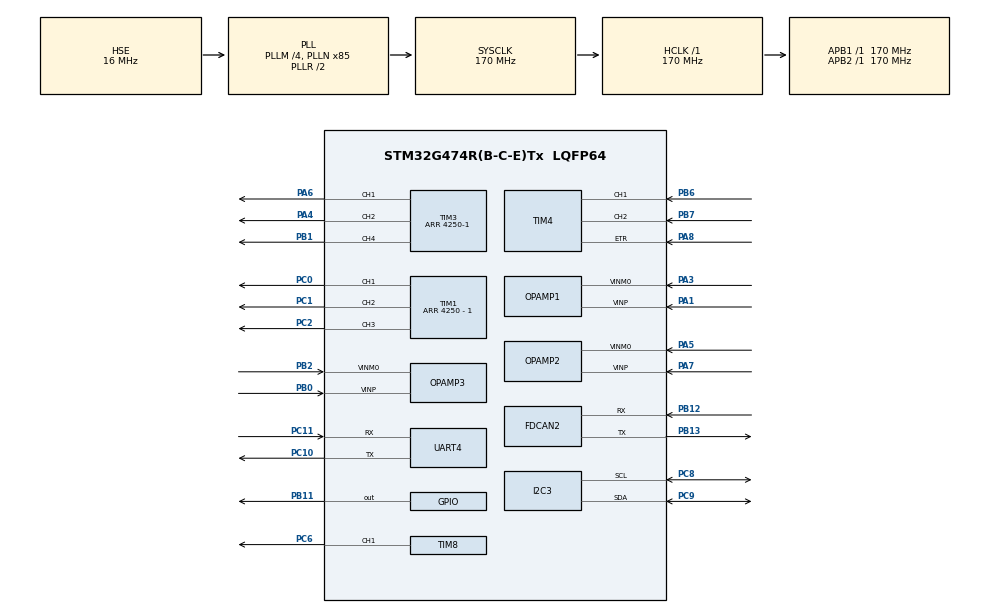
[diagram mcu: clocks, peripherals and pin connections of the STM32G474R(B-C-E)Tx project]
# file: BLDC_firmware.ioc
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ADC1.Channel-0\#ChannelRegularConversion=ADC_CHANNEL_VOPAMP1
ADC1.Channel-1\#ChannelRegularConversion=ADC_CHANNEL_VBAT
ADC1.DMAAccessModeView=ENABLE
ADC1.DMAContinuousRequests=ENABLE
ADC1.ExternalTrigConv=ADC_EXTERNALTRIG_T1_TRGO
ADC1.Mode=ADC_DUALMODE_REGSIMULT
ADC1.NbrOfConversion=2
ADC1.NbrOfConversionFlag=1
ADC1.OffsetNumber-1\#ChannelRegularConversion=ADC_OFFSET_NONE
ADC1.Rank-1\#ChannelRegularConversion=2
ADC1.SamplingTime-1\#ChannelRegularConversion=ADC_SAMPLETIME_2CYCLES_5
ADC1.master=1
ADC2.Channel-0\#ChannelRegularConversion=ADC_CHANNEL_VOPAMP2
ADC2.Channel-1\#ChannelRegularConversion=ADC_CHANNEL_VOPAMP3_ADC2
ADC2.DMAAccessModeView=ENABLE
ADC2.Mode=ADC_DUALMODE_REGSIMULT
ADC2.NbrOfConversion=2
ADC2.NbrOfConversionFlag=1
ADC2.OffsetNumber-0\#ChannelRegularConversion=ADC_OFFSET_NONE
ADC2.OffsetNumber-1\#ChannelRegularConversion=ADC_OFFSET_NONE
ADC2.OversamplingMode=DISABLE
ADC2.Rank-0\#ChannelRegularConversion=1
ADC2.Rank-1\#ChannelRegularConversion=2
ADC2.SamplingTime-0\#ChannelRegularConversion=ADC_SAMPLETIME_2CYCLES_5
ADC2.SamplingTime-1\#ChannelRegularConversion=ADC_SAMPLETIME_2CYCLES_5
Dma.ADC1.0.Direction=DMA_PERIPH_TO_MEMORY
Dma.ADC1.0.EventEnable=DISABLE
Dma.ADC1.0.Instance=DMA1_Channel1
Dma.ADC1.0.MemDataAlignment=DMA_MDATAALIGN_WORD
Dma.ADC1.0.MemInc=DMA_MINC_ENABLE
Dma.ADC1.0.Mode=DMA_CIRCULAR
Dma.ADC1.0.PeriphDataAlignment=DMA_PDATAALIGN_WORD
Dma.ADC1.0.PeriphInc=DMA_PINC_DISABLE
Dma.ADC1.0.Polarity=HAL_DMAMUX_REQ_GEN_RISING
Dma.ADC1.0.Priority=DMA_PRIORITY_HIGH
Dma.ADC1.0.RequestNumber=1
Dma.ADC1.0.SignalID=NONE
Dma.ADC1.0.SyncEnable=DISABLE
Dma.ADC1.0.SyncPolarity=HAL_DMAMUX_SYNC_NO_EVENT
Dma.ADC1.0.SyncRequestNumber=1
Dma.ADC1.0.SyncSignalID=NONE
Dma.Request0=ADC1
FDCAN2.CalculateBaudRateNominal=3541666
FDCAN2.CalculateTimeBitNominal=282
FDCAN2.CalculateTimeQuantumNominal=94.11764705882354
I2C3.Timing=0x40B285C2
Mcu.Family=STM32G4
Mcu.Name=STM32G474R(B-C-E)Tx
Mcu.Package=LQFP64
NVIC.ADC1_2_IRQn=true\:0\:0\:false\:false\:true\:true\:true\:true
NVIC.CORDIC_IRQn=true\:0\:0\:false\:false\:true\:true\:true\:true
NVIC.DMA1_Channel1_IRQn=true\:0\:0\:false\:false\:true\:false\:true\:true
NVIC.PriorityGroup=NVIC_PRIORITYGROUP_4
NVIC.TIM1_UP_TIM16_IRQn=true\:0\:0\:false\:false\:true\:true\:true\:true
NVIC.TIM6_DAC_IRQn=true\:0\:0\:false\:false\:true\:true\:true\:true
OPAMP1.PgaGain=OPAMP_PGA_GAIN_64_OR_MINUS_63
OPAMP2.PgaGain=OPAMP_PGA_GAIN_64_OR_MINUS_63
OPAMP3.PgaGain=OPAMP_PGA_GAIN_64_OR_MINUS_63
PA1.Mode=PGA Internally connected_IO0_BIAS
PA1.Signal=OPAMP1_VINP
PA13.Mode=Trace_Asynchronous_SW
PA13.Signal=SYS_JTMS-SWDIO
PA14.Mode=Trace_Asynchronous_SW
PA14.Signal=SYS_JTCK-SWCLK
PA3.Mode=PGA Internally connected_IO0_BIAS
PA3.Signal=OPAMP1_VINM0
PA4.Signal=S_TIM3_CH2
PA5.Mode=PGA Internally connected_IO0_BIAS
PA5.Signal=OPAMP2_VINM0
PA6.Signal=S_TIM3_CH1
PA7.Mode=PGA Internally connected_IO0_BIAS
PA7.Signal=OPAMP2_VINP
PA8.Signal=S_TIM4_ETR
PB0.Mode=PGA Internally connected_IO0_BIAS
PB0.Signal=OPAMP3_VINP
PB1.Signal=S_TIM3_CH4
PB11.Signal=GPIO_Output
PB12.Mode=FDCAN_Activate
PB12.Signal=FDCAN2_RX
PB13.Mode=FDCAN_Activate
PB13.Signal=FDCAN2_TX
PB2.Mode=PGA Internally connected_IO0_BIAS
PB2.Signal=OPAMP3_VINM0
PB3.Mode=Trace_Asynchronous_SW
PB3.Signal=SYS_JTDO-SWO
PB6.Signal=S_TIM4_CH1
PB7.Signal=S_TIM4_CH2
PC0.Signal=S_TIM1_CH1
PC1.Signal=S_TIM1_CH2
PC10.Mode=Asynchronous
PC10.Signal=UART4_TX
PC11.Mode=Asynchronous
PC11.Signal=UART4_RX
PC2.Signal=S_TIM1_CH3
PC6.Signal=S_TIM8_CH1
PC8.Mode=I2C
PC8.Signal=I2C3_SCL
PC9.Mode=I2C
PC9.Signal=I2C3_SDA
PF0-OSC_IN.Mode=HSE-External-Oscillator
PF0-OSC_IN.Signal=RCC_OSC_IN
PF1-OSC_OUT.Mode=HSE-External-Oscillator
PF1-OSC_OUT.Signal=RCC_OSC_OUT
ProjectManager.HeapSize=0x200
ProjectManager.StackSize=0x400
ProjectManager.TargetToolchain=CMake
RCC.ADC12Freq_Value=170000000
RCC.ADC345Freq_Value=170000000
RCC.AHBFreq_Value=170000000
RCC.APB1Freq_Value=170000000
RCC.APB1TimFreq_Value=170000000
RCC.APB2Freq_Value=170000000
RCC.APB2TimFreq_Value=170000000
RCC.CortexFreq_Value=170000000
RCC.EXTERNAL_CLOCK_VALUE=12288000
RCC.EnbaleCSS=true
RCC.HCLKFreq_Value=170000000
RCC.HSE_VALUE=16000000
RCC.HSI48_VALUE=48000000
RCC.HSI_VALUE=16000000
RCC.LSE_VALUE=32768
RCC.PLLM=RCC_PLLM_DIV4
RCC.PLLN=85
RCC.PLLSourceVirtual=RCC_PLLSOURCE_HSE
RCC.SYSCLKFreq_VALUE=170000000
RCC.SYSCLKSource=RCC_SYSCLKSOURCE_PLLCLK
RCC.USBFreq_Value=170000000
RCC.VCOOutputFreq_Value=340000000
SH.S_TIM1_CH1.0=TIM1_CH1,PWM Generation1 CH1
SH.S_TIM1_CH2.0=TIM1_CH2,PWM Generation2 CH2
SH.S_TIM1_CH3.0=TIM1_CH3,PWM Generation3 CH3
SH.S_TIM3_CH1.0=TIM3_CH1,PWM Generation1 CH1
SH.S_TIM3_CH2.0=TIM3_CH2,PWM Generation2 CH2
SH.S_TIM3_CH4.0=TIM3_CH4,PWM Generation4 CH4
SH.S_TIM4_CH1.0=TIM4_CH1,Encoder_Interface_w_index
SH.S_TIM4_CH2.0=TIM4_CH2,Encoder_Interface_w_index
SH.S_TIM4_ETR.0=TIM4_ETR,Encoder_Interface_w_index
SH.S_TIM8_CH1.0=TIM8_CH1,PWM Generation1 CH1
STMicroelectronics.X-CUBE-ALGOBUILD.1.5.0.LibraryCcDSPOoLibraryJjDSPOoLibrary=true
TIM1.BreakPolarity=TIM_BREAKPOLARITY_HIGH
TIM1.Channel-PWM\ Generation1\ CH1=TIM_CHANNEL_1
TIM1.Channel-PWM\ Generation2\ CH2=TIM_CHANNEL_2
TIM1.Channel-PWM\ Generation3\ CH3=TIM_CHANNEL_3
TIM1.CounterMode=TIM_COUNTERMODE_CENTERALIGNED1
TIM1.OCMode_PWM-PWM\ Generation1\ CH1=TIM_OCMODE_PWM2
TIM1.OCMode_PWM-PWM\ Generation2\ CH2=TIM_OCMODE_PWM2
TIM1.OCMode_PWM-PWM\ Generation3\ CH3=TIM_OCMODE_PWM2
TIM1.PeriodNoDither=4250 - 1
TIM1.RepetitionCounter=1
TIM1.TIM_MasterOutputTrigger=TIM_TRGO_UPDATE
TIM1.TIM_MasterOutputTrigger2=TIM_TRGO2_RESET
TIM3.Channel-PWM\ Generation1\ CH1=TIM_CHANNEL_1
TIM3.Channel-PWM\ Generation2\ CH2=TIM_CHANNEL_2
TIM3.Channel-PWM\ Generation4\ CH4=TIM_CHANNEL_4
TIM3.CounterMode=TIM_COUNTERMODE_CENTERALIGNED1
TIM3.OCMode_PWM-PWM\ Generation1\ CH1=TIM_OCMODE_PWM2
TIM3.OCMode_PWM-PWM\ Generation2\ CH2=TIM_OCMODE_PWM2
TIM3.OCMode_PWM-PWM\ Generation4\ CH4=TIM_OCMODE_PWM2
TIM3.PeriodNoDither=4250-1
TIM6.AutoReloadPreload=TIM_AUTORELOAD_PRELOAD_ENABLE
TIM6.PeriodNoDither=999
TIM6.Prescaler=169
TIM8.Channel-PWM\ Generation1\ CH1=TIM_CHANNEL_1
VP_ADC1_OPAMP_INTERNAL1.Mode=IN-OPAMP1
VP_ADC1_Vbat_Input.Mode=IN-Vbat
VP_ADC2_OPAMP_INTERNAL2.Mode=IN-OPAMP2
VP_ADC2_OPAMP_INTERNAL3.Mode=IN-OPAMP3
VP_CORDIC_VS_CORDIC.Mode=CORDIC_Activate
VP_STMicroelectronics.X-CUBE-ALGOBUILD_VS_DSPOoLibraryJjLibrary_1.5.0_1.5.0.Mode=DSPOoLibraryJjLibrary
VP_SYS_VS_DBSignals.Mode=DisableDeadBatterySignals
VP_TIM6_VS_ClockSourceINT.Mode=Enable_Timer
board=custom

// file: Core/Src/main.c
/* USER CODE BEGIN Header */
/**
  ******************************************************************************
  * @file           : main.c
  * @brief          : Main program body
  ******************************************************************************
  * @attention
  *
  * Copyright (c) 2025 STMicroelectronics.
  * All rights reserved.
  *
  * This software is licensed under terms that can be found in the LICENSE file
  * in the root directory of this software component.
  * If no LICENSE file comes with this software, it is provided AS-IS.
  *
  ******************************************************************************
  */
/* USER CODE END Header */
#include "main.h"
#include "adc.h"
#include "cordic.h"
#include "dma.h"
#include "fdcan.h"
#include "i2c.h"
#include "opamp.h"
#include "tim.h"
#include "usart.h"
#include "gpio.h"

/* USER CODE BEGIN Includes */
#include "bldc_controller.h"
#include <stdint.h>
#include <stdio.h>
#include <stdlib.h>
#include "main_app.h"

/* USER CODE END Includes */

/* USER CODE BEGIN PM */
#define ADC_FULL_SCALE_COUNTS 4095.0f
#define ADC_REFERENCE_VOLTAGE 3.3f
#define SHUNT_RESISTANCE_OHMS 0.01f
#define OPAMP_GAIN 64.0f

/* USER CODE END PM */

/* USER CODE BEGIN PV */

int _write(int file, char *ptr, int len)
{
  HAL_UART_Transmit(&huart4,(uint8_t *)ptr,len,10);
  return len;
}

/* USER CODE END PV */

void SystemClock_Config(void);

int main(void)
{

  /* MCU Configuration--------------------------------------------------------*/

  /* Reset of all peripherals, Initializes the Flash interface and the Systick. */
  HAL_Init();

  /* Configure the system clock */
  SystemClock_Config();

  /* Initialize all configured peripherals */
  MX_GPIO_Init();
  MX_DMA_Init();
  MX_TIM3_Init();
  MX_OPAMP1_Init();
  MX_OPAMP2_Init();
  MX_OPAMP3_Init();
  MX_TIM1_Init();
  MX_TIM4_Init();
  MX_FDCAN2_Init();
  MX_TIM8_Init();
  MX_I2C3_Init();
  MX_UART4_Init();
  MX_TIM6_Init();
  MX_ADC1_Init();
  MX_ADC2_Init();
  MX_CORDIC_Init();
  /* USER CODE BEGIN 2 */
  main_setup();
  /* USER CODE END 2 */

  /* Infinite loop */
  while (1)
  {

  }
}

void SystemClock_Config(void)
{
  RCC_OscInitTypeDef RCC_OscInitStruct = {0};
  RCC_ClkInitTypeDef RCC_ClkInitStruct = {0};

  /** Configure the main internal regulator output voltage
  */
  HAL_PWREx_ControlVoltageScaling(PWR_REGULATOR_VOLTAGE_SCALE1_BOOST);

  /** Initializes the RCC Oscillators according to the specified parameters
  * in the RCC_OscInitTypeDef structure.
  */
  RCC_OscInitStruct.OscillatorType = RCC_OSCILLATORTYPE_HSE;
  RCC_OscInitStruct.HSEState = RCC_HSE_ON;
  RCC_OscInitStruct.PLL.PLLState = RCC_PLL_ON;
  RCC_OscInitStruct.PLL.PLLSource = RCC_PLLSOURCE_HSE;
  RCC_OscInitStruct.PLL.PLLM = RCC_PLLM_DIV4;
  RCC_OscInitStruct.PLL.PLLN = 85;
  RCC_OscInitStruct.PLL.PLLP = RCC_PLLP_DIV2;
  RCC_OscInitStruct.PLL.PLLQ = RCC_PLLQ_DIV2;
  RCC_OscInitStruct.PLL.PLLR = RCC_PLLR_DIV2;
  if (HAL_RCC_OscConfig(&RCC_OscInitStruct) != HAL_OK)
  {
    Error_Handler();
  }

  /** Initializes the CPU, AHB and APB buses clocks
  */
  RCC_ClkInitStruct.ClockType = RCC_CLOCKTYPE_HCLK|RCC_CLOCKTYPE_SYSCLK
                              |RCC_CLOCKTYPE_PCLK1|RCC_CLOCKTYPE_PCLK2;
  RCC_ClkInitStruct.SYSCLKSource = RCC_SYSCLKSOURCE_PLLCLK;
  RCC_ClkInitStruct.AHBCLKDivider = RCC_SYSCLK_DIV1;
  RCC_ClkInitStruct.APB1CLKDivider = RCC_HCLK_DIV1;
  RCC_ClkInitStruct.APB2CLKDivider = RCC_HCLK_DIV1;

  if (HAL_RCC_ClockConfig(&RCC_ClkInitStruct, FLASH_LATENCY_4) != HAL_OK)
  {
    Error_Handler();
  }

  /** Enables the Clock Security System
  */
  HAL_RCC_EnableCSS();
}

void Error_Handler(void)
{
  __disable_irq();
  while (1)
  {
  }
}
